# UPD70F3508 register map
Vendor: Renesas; Series: V850E2/Px4; File version: 1.0
CPU: other r0p0, little endian, no MPU, FPU, 4 interrupt priority bits
Registers are 8-bit, read-write, reset 0x0 unless marked. A register's access mark holds for its fields unless they carry their own. Offsets are from the block's base; [hi:lo] are bit positions; lines under a group give offsets from that group; {n}, {i} and the like mark numbered series.

## FCLA0 — Edge detection filter group 0 - NMI (Table 2-65)
Base 0xFF414000
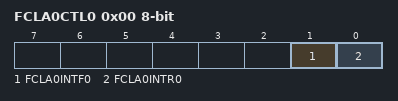
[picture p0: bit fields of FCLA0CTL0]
0x00 FCLA0CTL0 — Edge detection filter control register for NMI
  [1] FCLA0INTF0 — Falling edge detection: 0=disabled, 1=enabled
  [0] FCLA0INTR0 — Rising edge detection: 0=disabled, 1=enabled

## FCLA1 — Edge detection filter group 1 - INTP0..7 (Table 2-65)
Base 0xFF414100
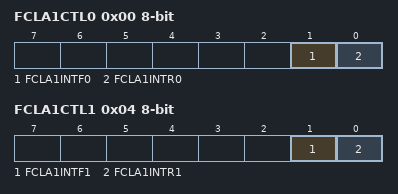
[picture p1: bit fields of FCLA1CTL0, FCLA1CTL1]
0x00 FCLA1CTL0 — Edge detection filter control for INTP0
  [1] FCLA1INTF0 — Falling edge: 0=disabled, 1=enabled
  [0] FCLA1INTR0 — Rising edge: 0=disabled, 1=enabled
0x04 FCLA1CTL1 — Edge detection filter control for INTP1
  [1] FCLA1INTF1 — Falling edge enable
  [0] FCLA1INTR1 — Rising edge enable
{0x0+4i} FCLA1CTL{i} (i=2..7) — Edge detection filter control for INTP{i}

## FCLA2 — Edge detection filter group 2 - INTP8..10 (Table 2-65)
Base 0xFF414200
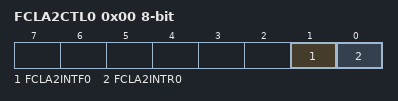
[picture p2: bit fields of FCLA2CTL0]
0x00 FCLA2CTL0 — Edge detection filter control for INTP8
  [1] FCLA2INTF0 — Falling edge enable
  [0] FCLA2INTR0 — Rising edge enable
0x04 FCLA2CTL1 — Edge detection filter control for INTP9
0x08 FCLA2CTL2 — Edge detection filter control for INTP10

## RESET — Reset Controller (protection command, status, reset flags, software reset)
Base 0xFF420014
0x00 CSCPCMD wo — Protection Command Register — write A5H to begin protected-register write sequence
0x04 CSCPS ro — Protection Status Register — reports whether the protected write sequence succeeded
  [0] CSCPRERR — Protected write sequence error: 0=no error, 1=error occurred
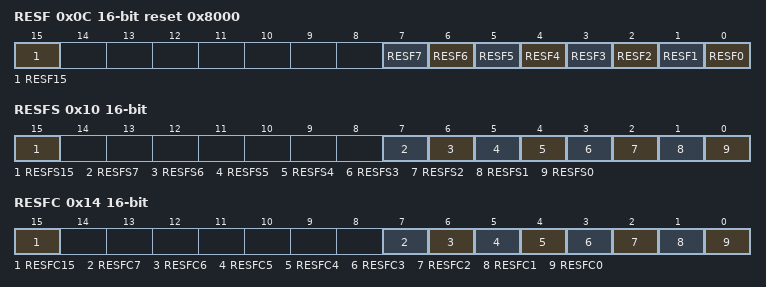
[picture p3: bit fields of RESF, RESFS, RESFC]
0x0C RESF 16-bit ro reset 0x8000 — Reset Source Register — flags indicating which reset sources have fired since last SYSRES
  [15] RESF15 — External reset (RESET/DBRES) flag: 1=RESET or DBRES occurred
  [7] RESF7 — Self-diagnostic BIST reset (BISTRES) flag: 1=BISTRES occurred
  [6] RESF6 — Safety guardian reset (SGARES) flag: 1=SGARES occurred
  [5] RESF5 — Clock monitor CLMA2 reset (CLMA2RES) flag: 1=CLMA2RES occurred
  [4] RESF4 — Clock monitor CLMA1 reset (CLMA1RES) flag: 1=CLMA1RES occurred
  [3] RESF3 — Clock monitor CLMA0 reset (CLMA0RES) flag: 1=CLMA0RES occurred
  [2] RESF2 — Watchdog timer WDTA0 reset (WDTA0RES) flag: 1=WDTA0RES occurred
  [1] RESF1 — Software reset (SWRES) flag: 1=SWRES occurred
  [0] RESF0 — Low voltage indicator reset (LVIRES) flag: 1=LVIRES occurred
0x10 RESFS 16-bit — Reset Source Set Register — software-force set of RESF flags (test use); reads as 0000H
  [15] RESFS15 — Force-set external reset flag (RESF.RESF15): 1=sets flag
  [7] RESFS7 — Force-set BISTRES flag (RESF.RESF7): 1=sets flag
  [6] RESFS6 — Force-set SGARES flag (RESF.RESF6): 1=sets flag
  [5] RESFS5 — Force-set CLMA2RES flag (RESF.RESF5): 1=sets flag
  [4] RESFS4 — Force-set CLMA1RES flag (RESF.RESF4): 1=sets flag
  [3] RESFS3 — Force-set CLMA0RES flag (RESF.RESF3): 1=sets flag
  [2] RESFS2 — Force-set WDTA0RES flag (RESF.RESF2): 1=sets flag
  [1] RESFS1 — Force-set SWRES flag (RESF.RESF1): 1=sets flag
  [0] RESFS0 — Force-set LVIRES flag (RESF.RESF0): 1=sets flag
0x14 RESFC 16-bit — Reset Source Clear Register — clears RESF flags; reads as 0000H
  [15] RESFC15 — Clear external reset flag (RESF.RESF15): 1=clears flag
  [7] RESFC7 — Clear BISTRES flag (RESF.RESF7): 1=clears flag
  [6] RESFC6 — Clear SGARES flag (RESF.RESF6): 1=clears flag
  [5] RESFC5 — Clear CLMA2RES flag (RESF.RESF5): 1=clears flag
  [4] RESFC4 — Clear CLMA1RES flag (RESF.RESF4): 1=clears flag
  [3] RESFC3 — Clear CLMA0RES flag (RESF.RESF3): 1=clears flag
  [2] RESFC2 — Clear WDTA0RES flag (RESF.RESF2): 1=clears flag
  [1] RESFC1 — Clear SWRES flag (RESF.RESF1): 1=clears flag
  [0] RESFC0 — Clear LVIRES flag (RESF.RESF0): 1=clears flag
0x18 SWRESA wo — Software Reset Register — write 1 to bit 0 to trigger software reset SWRES; protected by CSCPCMD sequence; reads as 00H
  [0] SWRESA — Software reset control: 0=no effect, 1=generate SWRES
